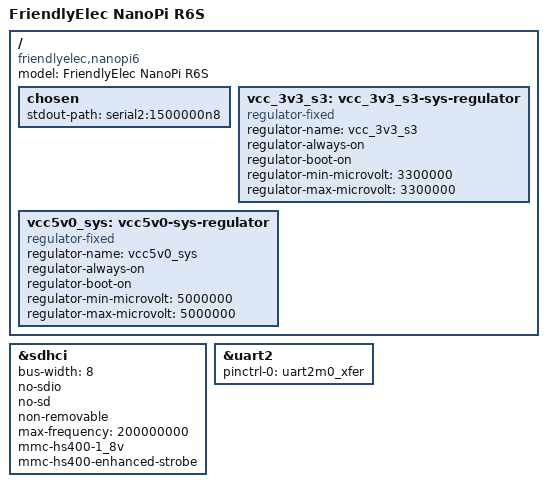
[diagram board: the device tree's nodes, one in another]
// SPDX-License-Identifier: (GPL-2.0+ OR MIT)

/dts-v1/;

#include <dt-bindings/gpio/gpio.h>
#include "rk3588s.dtsi"

/ {
	model = "FriendlyElec NanoPi R6S";
	compatible = "friendlyelec,nanopi6", "rockchip,rk3588";


	chosen {
		stdout-path = "serial2:1500000n8";
	};

	vcc_3v3_s3: vcc_3v3_s3-sys-regulator {
                compatible = "regulator-fixed";
                regulator-name = "vcc_3v3_s3";
                regulator-always-on;
                regulator-boot-on;
                regulator-min-microvolt = <3300000>;
                regulator-max-microvolt = <3300000>;
        };

	vcc5v0_sys: vcc5v0-sys-regulator {
		compatible = "regulator-fixed";
		regulator-name = "vcc5v0_sys";
		regulator-always-on;
		regulator-boot-on;
		regulator-min-microvolt = <5000000>;
		regulator-max-microvolt = <5000000>;
	};
};

&sdhci {
	bus-width = <8>;
	no-sdio;
	no-sd;
	non-removable;
	max-frequency = <200000000>;
	mmc-hs400-1_8v;
	mmc-hs400-enhanced-strobe;
	status = "okay";
};

&uart2 {
	pinctrl-0 = <&uart2m0_xfer>;
	status = "okay";
};
